# SKEAZN84 register map
Vendor: Freescale Semiconductor, Inc.; File version: 1.6
CPU: CM0PLUS r0p0, little endian, no MPU, no FPU, 0x2 interrupt priority bits, 0x0 interrupts
Registers are 32-bit, read-write, reset 0x0 unless marked. A register's access mark holds for its fields unless they carry their own. Offsets are from the block's base; [hi:lo] are bit positions; {n}, {i} and the like mark numbered series; 'fields as' and 'values as' point back to an identical list.

## FTM0 — FlexTimer Module
Base 0x40038000; register names take the prefix FTM0_
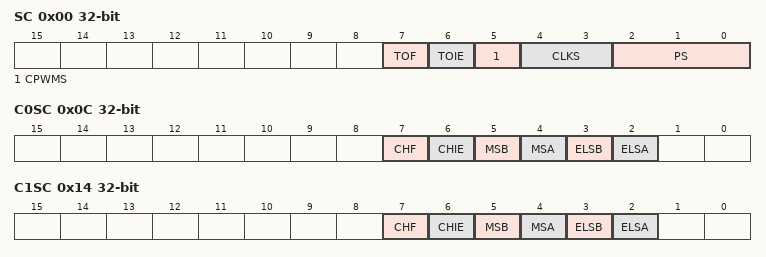
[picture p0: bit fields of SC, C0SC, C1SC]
0x00 SC — Status And Control
  [7] TOF ro — Timer Overflow Flag
    0=FTM counter has not overflowed; 1=FTM counter has overflowed
  [6] TOIE — Timer Overflow Interrupt Enable
    0=Disable TOF interrupts. Use software polling.; 1=Enable TOF interrupts. An interrupt is generated when TOF equals one.
  [5] CPWMS — Center-Aligned PWM Select
    0=FTM counter operates in Up Counting mode; 1=FTM counter operates in Up-Down Counting mode
  [4:3] CLKS — Clock Source Selection
    0=No clock selected. This in effect disables the FTM counter.; 1=System clock; 2=Fixed frequency clock; 3=External clock
  [2:0] PS — Prescale Factor Selection
    0=Divide by 1; 1=Divide by 2; 2=Divide by 4; 3=Divide by 8; 4=Divide by 16; 5=Divide by 32; 6=Divide by 64; 7=Divide by 128
0x04 CNT — Counter
  [15:0] COUNT — Counter Value
0x08 MOD — Modulo
  [15:0] MOD
0x0C C0SC — Channel (n) Status And Control
  [7] CHF ro — Channel Flag
    0=No channel event has occurred; 1=A channel event has occurred
  [6] CHIE — Channel Interrupt Enable
    0=Disable channel interrupts. Use software polling.; 1=Enable channel interrupts
  [5] MSB — Channel Mode Select
  [4] MSA — Channel Mode Select
  [3] ELSB — Edge or Level Select
  [2] ELSA — Edge or Level Select
0x10 C0V — Channel (n) Value
  [15:0] VAL — Channel Value
0x14 C1SC — Channel (n) Status And Control
  fields as C0SC
0x18 C1V — Channel (n) Value
  [15:0] VAL — Channel Value

## RTC — Real-time counter
Base 0x4003D000; register names take the prefix RTC_
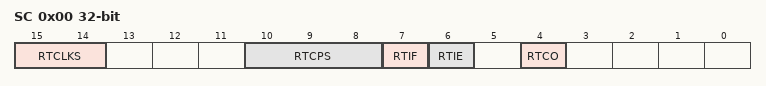
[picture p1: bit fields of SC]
0x00 SC — RTC Status and Control Register
  [15:14] RTCLKS — Real-Time Clock Source Select
    0=External clock source; 1=Real-time clock source is 1 kHz (LPOCLK); 2=Internal reference clock (ICSIRCLK); 3=Bus clock
  [10:8] RTCPS — Real-Time Clock Prescaler Select
    0=Off; 1=If RTCLKS = x0, it is 1; if RTCLKS = x1, it is 128; 2=If RTCLKS = x0, it is 2; if RTCLKS = x1, it is 256; 3=If RTCLKS = x0, it is 4; if RTCLKS = x1, it is 512; 4=If RTCLKS = x0, it is 8; if RTCLKS = x1, it is 1024; 5=If RTCLKS = x0, it is 16; if RTCLKS = x1, it is 2048; 6=If RTCLKS = x0, it is 32; if RTCLKS = x1, it is 100; 7=If RTCLKS = x0, it is 64; if RTCLKS = x1, it is 1000
  [7] RTIF — Real-Time Interrupt Flag
    0=RTC counter has not reached the value in the RTC modulo register; 1=RTC counter has reached the value in the RTC modulo register
  [6] RTIE — Real-Time Interrupt Enable
    0=Real-time interrupt requests are disabled. Use software polling.; 1=Real-time interrupt requests are enabled
  [4] RTCO — Real-Time Counter Output
    0=Real-time counter output disabled; 1=Real-time counter output enabled
0x04 MOD — RTC Modulo Register
  [15:0] MOD — RTC Modulo
0x08 CNT ro — RTC Counter Register
  [15:0] CNT — RTC Count

## PORT — Port control and interrupts
Base 0x40049000; register names take the prefix PORT_
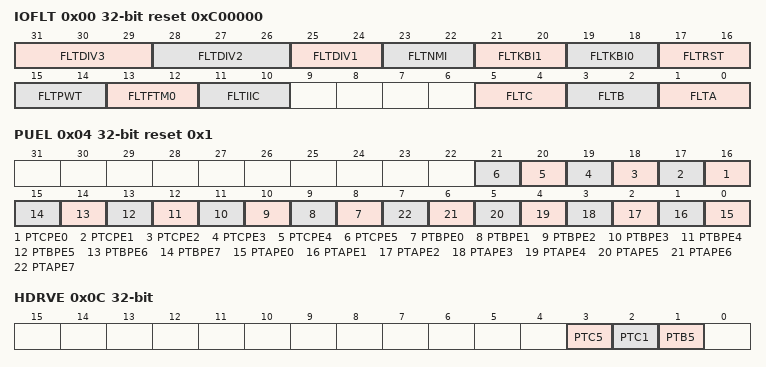
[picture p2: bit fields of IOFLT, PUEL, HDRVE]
0x00 IOFLT reset 0xC00000 — Port Filter Register
  [31:29] FLTDIV3 — Filter Division Set 3
    0=LPOCLK; 1=LPOCLK/2; 2=LPOCLK/4; 3=LPOCLK/8; 4=LPOCLK/16; 5=LPOCLK/32; 6=LPOCLK/64; 7=LPOCLK/128
  [28:26] FLTDIV2 — Filter Division Set 2
    0=BUSCLK/32; 1=BUSCLK/64; 2=BUSCLK/128; 3=BUSCLK/256; 4=BUSCLK/512; 5=BUSCLK/1024; 6=BUSCLK/2048; 7=BUSCLK/4096
  [25:24] FLTDIV1 — Filter Division Set 1
    0=BUSCLK/2; 1=BUSCLK/4; 2=BUSCLK/8; 3=BUSCLK/16
  [23:22] FLTNMI — Filter Selection for Input from NMI
    0=No filter; 1=Selects FLTDIV1, and will switch to FLTDIV3 in Stop mode automatically; 2=Selects FLTDIV2, and will switch to FLTDIV3 in Stop mode automatically; 3=FLTDIV3
  [21:20] FLTKBI1 — Filter Selection for Input from KBI1
    values as FLTNMI
  [19:18] FLTKBI0 — Filter selection for Input from KBI0
    values as FLTNMI
  [17:16] FLTRST — Filter Selection for Input from RESET/IRQ
    values as FLTNMI
  [15:14] FLTPWT — Filter Selection For Input from PWT_IN1/PWT_IN0
    0=No filter; 1=Select FLTDIV1; 2=Select FLTDIV2; 3=Select FLTDIV3
  [13:12] FLTFTM0 — Filter Selection For Input from FTM0CH0/FTM0CH1
    values as FLTPWT
  [11:10] FLTIIC — Filter Selection For Input from SCL/SDA
    0=No filter; 1=Select FLTDIV1; 2=Select FLTDIV2; 3=Select BUSCLK
  [5:4] FLTC — Filter Selection for Input from PTC
    0=BUSCLK; 1=FLTDIV1; 2=FLTDIV2; 3=FLTDIV3
  [3:2] FLTB — Filter Selection for Input from PTB
    0=BUSCLK; 1=FLTDIV1; 2=FLTDIV2; 3=FLTDIV3
  [1:0] FLTA — Filter Selection for Input from PTA
    0=BUSCLK; 1=FLTDIV1; 2=FLTDIV2; 3=FLTDIV3
0x04 PUEL reset 0x1 — Port Pullup Enable Low Register
  [n+16] PTCPE{n} (n=0..5) — Pull Enable for Port C Bit {n}
    0=Pullup is disabled for port C bit {n}; 1=Pullup is enabled for port C bit {n}
  [n+8] PTBPE{n} (n=0..7) — Pull Enable for Port B Bit {n}
    0=Pullup is disabled for port B bit {n}; 1=Pullup is enabled for port B bit {n}
  [n] PTAPE{n} (n=0..7) — Pull Enable for Port A Bit {n}
    0=Pullup is disabled for port A bit {n}; 1=Pullup is enabled for port A bit {n}
0x0C HDRVE — Port High Drive Enable Register
  [3] PTC5 — High Current Drive Capability of PTC5
    0=PTC5 is disabled to offer high current drive capability; 1=PTC5 is enabled to offer high current drive capability
  [2] PTC1 — High Current Drive Capability of PTC1
    0=PTC1 is disabled to offer high current drive capability; 1=PTC1 is enabled to offer high current drive capability
  [1] PTB5 — High Current Drive Capability of PTB5
    0=PTB5 is disabled to offer high current drive capability; 1=PTB5 is enabled to offer high current drive capability
